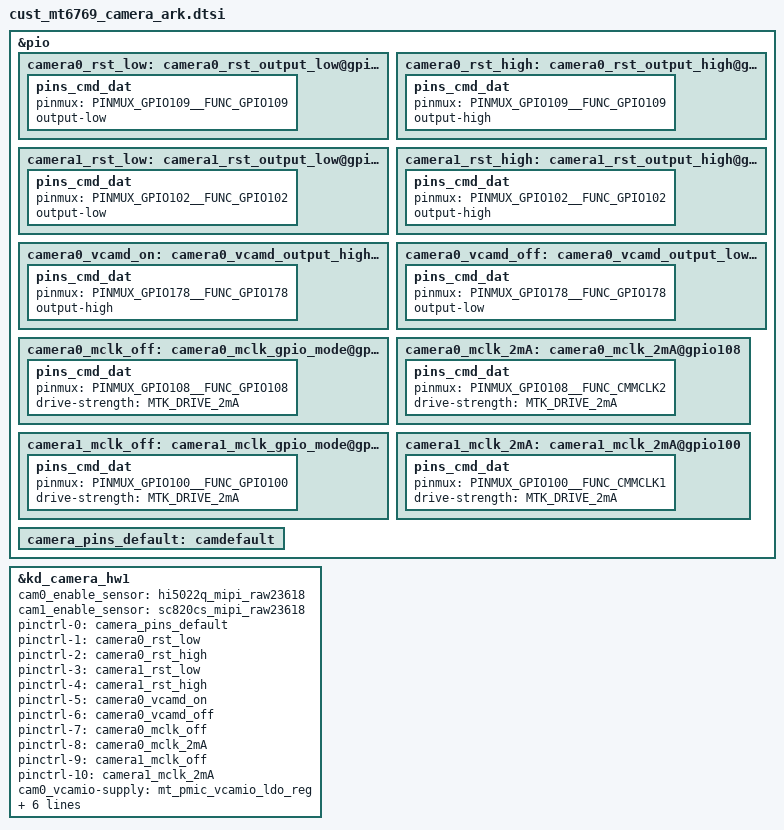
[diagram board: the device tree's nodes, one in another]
/*
 * Copyright (c) 2019 MediaTek Inc.
 *
 * This program is free software; you can redistribute it and/or modify
 * it under the terms of the GNU General Public License version 2 as
 * published by the Free Software Foundation.
 *
 * This program is distributed in the hope that it will be useful,
 * but WITHOUT ANY WARRANTY; without even the implied warranty of
 * MERCHANTABILITY or FITNESS FOR A PARTICULAR PURPOSE.  See the
 * GNU General Public License for more details.
 */
/* CAMERA GPIO standardization */
&pio {
	camera0_rst_low: camera0_rst_output_low@gpio109 {
		pins_cmd_dat {
			pinmux = <PINMUX_GPIO109__FUNC_GPIO109>;
			output-low;
		};
	};
	camera0_rst_high: camera0_rst_output_high@gpio109 {
		pins_cmd_dat {
			pinmux = <PINMUX_GPIO109__FUNC_GPIO109>;
			output-high;
		};
	};
	camera1_rst_low: camera1_rst_output_low@gpio102 {
		pins_cmd_dat {
			pinmux = <PINMUX_GPIO102__FUNC_GPIO102>;
			output-low;
		};
	};
	camera1_rst_high: camera1_rst_output_high@gpio102 {
		pins_cmd_dat {
			pinmux = <PINMUX_GPIO102__FUNC_GPIO102>;
			output-high;
		};
	};
	camera0_vcamd_on: camera0_vcamd_output_high@gpio178 {
		pins_cmd_dat {
			pinmux = <PINMUX_GPIO178__FUNC_GPIO178>;
			output-high;
		};
	};
	camera0_vcamd_off: camera0_vcamd_output_low@gpio178 {
		pins_cmd_dat {
			pinmux = <PINMUX_GPIO178__FUNC_GPIO178>;
			output-low;
		};
	};
	camera0_mclk_off: camera0_mclk_gpio_mode@gpio108 {
		pins_cmd_dat {
			pinmux = <PINMUX_GPIO108__FUNC_GPIO108>;
			drive-strength = <MTK_DRIVE_2mA>;
		};
	};
	camera0_mclk_2mA: camera0_mclk_2mA@gpio108 {
		pins_cmd_dat {
			pinmux = <PINMUX_GPIO108__FUNC_CMMCLK2>;
			drive-strength = <MTK_DRIVE_2mA>;
		};
	};
	camera1_mclk_off: camera1_mclk_gpio_mode@gpio100 {
		pins_cmd_dat {
			pinmux = <PINMUX_GPIO100__FUNC_GPIO100>;
			drive-strength = <MTK_DRIVE_2mA>;
		};
	};
	camera1_mclk_2mA: camera1_mclk_2mA@gpio100 {
		pins_cmd_dat {
			pinmux = <PINMUX_GPIO100__FUNC_CMMCLK1>;
			drive-strength = <MTK_DRIVE_2mA>;
		};
	};
	camera_pins_default: camdefault {
	};

};

&kd_camera_hw1 {
	cam0_enable_sensor = "hi5022q_mipi_raw23618";
	cam1_enable_sensor = "sc820cs_mipi_raw23618";

	pinctrl-names = "default",
			"cam0_rst0", "cam0_rst1",
			"cam1_rst0", "cam1_rst1",
			"cam0_vcamd_on",
			"cam0_vcamd_off",

			"cam0_mclk_off",
			"cam0_mclk_2mA",

			"cam1_mclk_off",
			"cam1_mclk_2mA";

	pinctrl-0 = <&camera_pins_default>;
	pinctrl-1 = <&camera0_rst_low>;
	pinctrl-2 = <&camera0_rst_high>;
	pinctrl-3 = <&camera1_rst_low>;
	pinctrl-4 = <&camera1_rst_high>;
	pinctrl-5 = <&camera0_vcamd_on>;
	pinctrl-6 = <&camera0_vcamd_off>;
	pinctrl-7 = <&camera0_mclk_off>;
	pinctrl-8 = <&camera0_mclk_2mA>;
	pinctrl-9 = <&camera1_mclk_off>;
	pinctrl-10 = <&camera1_mclk_2mA>;

	cam0_vcamio-supply = <&mt_pmic_vcamio_ldo_reg>;
	cam0_vcamd-supply = <&mt_pmic_vcamd_ldo_reg>;
	cam0_vcama-supply = <&mt_pmic_vcama2_ldo_reg>;
	cam0_vcamaf-supply = <&mt_pmic_vio28_ldo_reg>;

	cam1_vcamio-supply = <&mt_pmic_vcamio_ldo_reg>;
	cam1_vcamd-supply = <&mt_pmic_vcamd_ldo_reg>;
	cam1_vcama-supply = <&mt_pmic_vcama1_ldo_reg>;

	status = "okay";
};

/* CAMERA GPIO end */
